# RZT2H register map
Vendor: Renesas Electronics Corporation; Series: RZT; File version: 1.00.00
CPU: other r0p0, little endian, MPU, no FPU, VTOR, 4 interrupt priority bits, 624 interrupts
Registers are 32-bit, read-write, reset 0x0 unless marked. A register's access mark holds for its fields unless they carry their own. Offsets are from the block's base; [hi:lo] are bit positions; {n}, {i} and the like mark numbered series; 'fields as' and 'values as' point back to an identical list.

## PCIE0 (part 2 of 2) — PCI Express 3.0 Interface 0
Base 0x92100000
Same registers: PCIE1 0x92110000
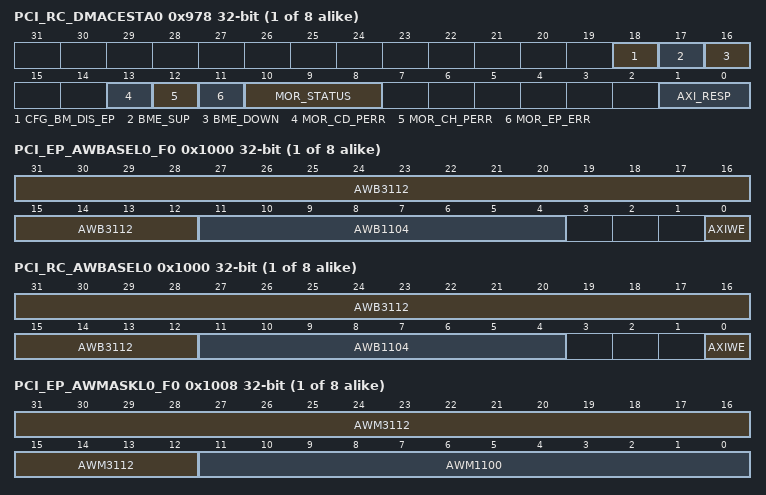
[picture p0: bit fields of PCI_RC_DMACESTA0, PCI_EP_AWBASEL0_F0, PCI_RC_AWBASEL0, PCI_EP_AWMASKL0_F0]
{0x978+0x80*i} PCI_RC_DMACESTA{i} (i=0..7) ro (alternate view of PCI_EP_DMACESTA{i}) — DMAC Error Status Register {i}
  [18] CFG_BM_DIS_EP — CHx_ERR is set when the macro operates as an End Point and detects the state of Bus Master Enable Off (Configuration Space 0x004 bit [2] = 0). Holds value until CHx_ERR is cleared.
  [17] BME_SUP — It is set when a sleep signal from the PCIe core is detected as a cause for setting CHx_ERR. Holds value until CHx_ERR is cleared.
  [16] BME_DOWN — It is set when a stop signal from the PCIe core is detected as a cause for setting CHx_ERR. Holds value until CHx_ERR is cleared.
  [13] MOR_CD_PERR — It is set when MOR_CD_PERR is detected as a set factor for CHx_ERR. Holds value until CHx_ERR is cleared.
  [12] MOR_CH_PERR — It is set when MOR_CH_PERR is detected as a set factor for CHx_ERR. Holds value until CHx_ERR is cleared.
  [11] MOR_EP_ERR — It is set when it is Poisoned Completion as a set factor of CHx_ERR. Holds value until CHx_ERR is cleared.
  [10:8] MOR_STATUS — Indicates the value when MOR_STATUS is other than 000b (Success) as a set factor of CHx_ERR. Holds value until CHx_ERR is cleared.
    0=initial value; 1=Unsupported Request; 2=CRS; 3=Completion Timeout; 4=Completer Abort; 5=Unexpected Completion; 7=Mismatched Length (Length Overrun)
  [1:0] AXI_RESP — Displays the slave response during AXI Master transactions.
    0=Initial value
{0x1000+0x20*i} PCI_EP_AWBASEL{i}_F0 (i=0..7) — AXI Window Base (Lower) Register {i} (Function #0)
  [31:12] AWB3112 — AWBase[31:12]
  [11:4] AWB1104 ro — AWBase[11:4]
  [0] AXIWE — AXI Window Enable
    0=Window disabled; 1=Window enabled
{0x1000+0x20*i} PCI_RC_AWBASEL{i} (i=0..7) (alternate view of PCI_EP_AWBASEL{i}_F0) — AXI Window Base (Lower) Register {i}
  [31:12] AWB3112 — AWBase31:12
  [11:4] AWB1104 ro — AWBase11:4
  [0] AXIWE — AXI Window Enable
    0=Window disabled; 1=Window enabled
{0x1004+0x20*i} PCI_EP_AWBASEU{i}_F0 (i=0..7) — AXI Window Base (Upper) Register {i} (Function #0)
  [31:0] AWB6332 — AWBase[63:32]
{0x1004+0x20*i} PCI_RC_AWBASEU{i} (i=0..7) (alternate view of PCI_EP_AWBASEU{i}_F0) — AXI Window Base (Upper) Register {i}
  [31:0] AWB6332 — AWBase63:32
{0x1008+0x20*i} PCI_EP_AWMASKL{i}_F0 (i=0..7) — AXI Window Mask (Lower) Register {i} (Function #0)
  [31:12] AWM3112 — AWMask[31:12]
  [11:0] AWM1100 ro — AWMask[11:0]
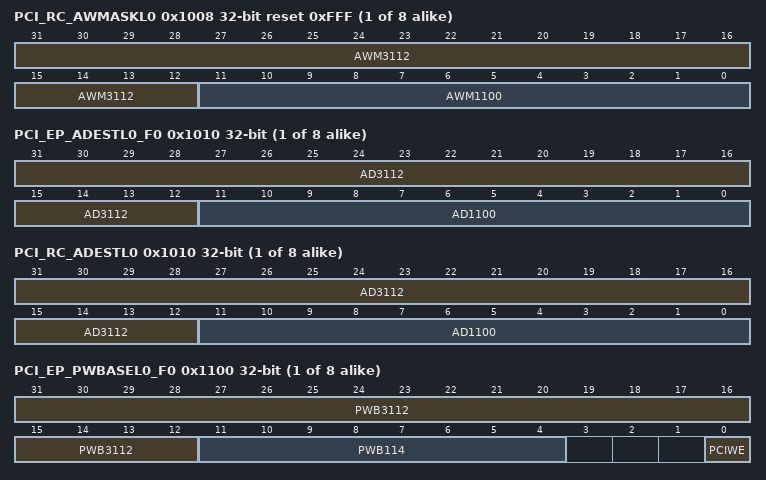
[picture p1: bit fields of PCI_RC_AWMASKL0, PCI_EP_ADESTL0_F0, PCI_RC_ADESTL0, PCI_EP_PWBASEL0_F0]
{0x1008+0x20*i} PCI_RC_AWMASKL{i} (i=0..7) reset 0xFFF (alternate view of PCI_EP_AWMASKL{i}_F0) — AXI Window Mask (Lower) Register {i}
  [31:12] AWM3112 — AWMask31:12
  [11:0] AWM1100 ro — AWMask11:0
{0x100C+0x20*i} PCI_EP_AWMASKU{i}_F0 (i=0..7) — AXI Window Mask (Upper) Register {i} (Function #0)
  [30:0] AWM6232 — AWMask[62:32]
{0x100C+0x20*i} PCI_RC_AWMASKU{i} (i=0..7) (alternate view of PCI_EP_AWMASKU{i}_F0) — AXI Window Mask Upper Register {i}
  [30:0] AWM6232 — AWMask62:32
{0x1010+0x20*i} PCI_EP_ADESTL{i}_F0 (i=0..7) — AXI Destination (Lower) Register {i} (Function #0)
  [31:12] AD3112 — ADest[31:12]
  [11:0] AD1100 ro — ADest[11:0]
{0x1010+0x20*i} PCI_RC_ADESTL{i} (i=0..7) (alternate view of PCI_EP_ADESTL{i}_F0) — AXI Destination (Lower) Register {i}
  [31:12] AD3112 — ADest31:12
  [11:0] AD1100 ro — ADest11:0
{0x1014+0x20*i} PCI_EP_ADESTU{i}_F0 (i=0..7) — AXI Destination (Upper) Register {i} (Function #0)
  [31:0] AD6332 — ADest[63:32]
{0x1014+0x20*i} PCI_RC_ADESTU{i} (i=0..7) (alternate view of PCI_EP_ADESTU{i}_F0) — AXI Destination (Upper) Register {i}
  [31:0] AD6332 — ADest63:32
{0x1100+0x20*i} PCI_EP_PWBASEL{i}_F0 (i=0..7) — PCIe Window Base (Lower) Register {i} (Function #0)
  [31:12] PWB3112 — PWBase[31:12]
  [11:4] PWB114 ro — PWBase[11:4]
  [0] PCIWE — PCIe Window Enable
    0=Window disabled; 1=Window enabled
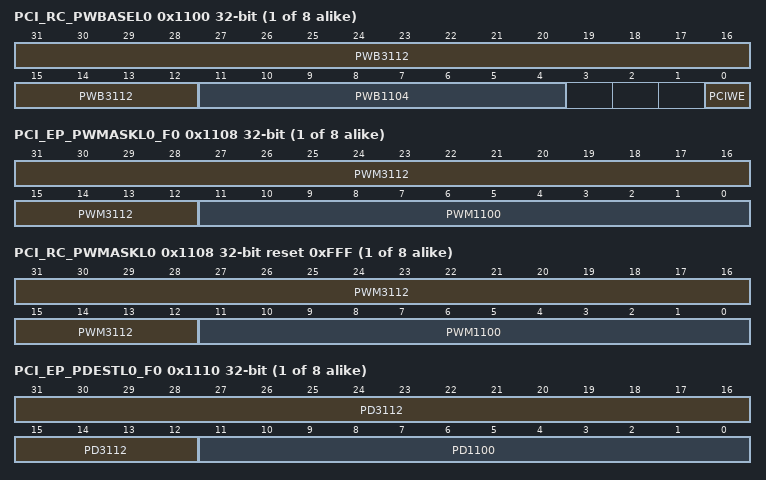
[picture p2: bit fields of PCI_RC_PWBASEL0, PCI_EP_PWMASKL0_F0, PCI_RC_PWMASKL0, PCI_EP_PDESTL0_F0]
{0x1100+0x20*i} PCI_RC_PWBASEL{i} (i=0..7) (alternate view of PCI_EP_PWBASEL{i}_F0) — PCIe Window Base (Lower) Register {i}
  [31:12] PWB3112 — PWBase31:12
  [11:4] PWB1104 ro — PWBase11:4
  [0] PCIWE — PCIe Window Enable
    0=Window disabled; 1=Window enabled
{0x1104+0x20*i} PCI_EP_PWBASEU{i}_F0 (i=0..7) — PCIe Window Base (Upper) Register {i} (Function #0)
  [31:0] PWB6332 — PWBase[63:32]
{0x1104+0x20*i} PCI_RC_PWBASEU{i} (i=0..7) (alternate view of PCI_EP_PWBASEU{i}_F0) — PCIe Window Base (Upper) Register {i}
  [31:0] PWB6332 — PWBase63:32
{0x1108+0x20*i} PCI_EP_PWMASKL{i}_F0 (i=0..7) — PCIe Window Mask (Lower) Register {i} (Function #0)
  [31:12] PWM3112 — PWMask[31:12]
  [11:0] PWM1100 ro — PWMask[11:0]
{0x1108+0x20*i} PCI_RC_PWMASKL{i} (i=0..7) reset 0xFFF (alternate view of PCI_EP_PWMASKL{i}_F0) — PCIe Window Mask (Lower) Register {i}
  [31:12] PWM3112 — PWMask31:12
  [11:0] PWM1100 ro — PWMask
{0x110C+0x20*i} PCI_EP_PWMASKU{i}_F0 (i=0..7) — PCIe Window Mask (Upper) Register {i} (Function #0)
  [30:0] PWM6232 — PWMask[62:32]
{0x110C+0x20*i} PCI_RC_PWMASKU{i} (i=0..7) (alternate view of PCI_EP_PWMASKU{i}_F0) — PCIe Window Mask (Upper) Register {i}
  [30:0] PWM6232 — PWMask62:32
{0x1110+0x20*i} PCI_EP_PDESTL{i}_F0 (i=0..7) — PCIe Destination (Lower) Register {i} (Function #0)
  [31:12] PD3112 — PDest[31:12]
  [11:0] PD1100 ro — PDest[11:0]
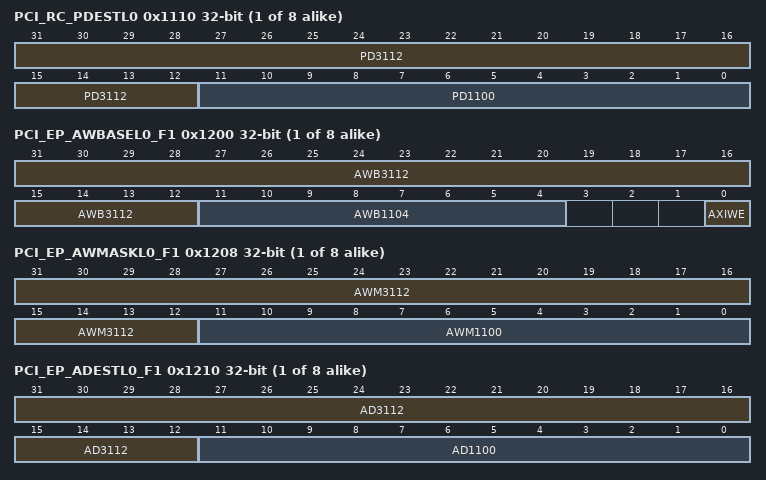
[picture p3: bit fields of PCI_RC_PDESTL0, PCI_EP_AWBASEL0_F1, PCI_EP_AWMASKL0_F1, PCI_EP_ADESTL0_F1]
{0x1110+0x20*i} PCI_RC_PDESTL{i} (i=0..7) (alternate view of PCI_EP_PDESTL{i}_F0) — PCIe Destination (Lower) Register {i}
  [31:12] PD3112 — PDest31:12
  [11:0] PD1100 ro — PDest11:0
{0x1114+0x20*i} PCI_EP_PDESTU{i}_F0 (i=0..7) — PCIe Destination (Upper) Register {i} (Function #0)
  [31:0] PD6332 — PDest[63:32]
{0x1114+0x20*i} PCI_RC_PDESTU{i} (i=0..7) (alternate view of PCI_EP_PDESTU{i}_F0) — PCIe Destination (Upper) Register {i}
  [31:0] PD6332 — PDest63:32
{0x1200+0x20*i} PCI_EP_AWBASEL{i}_F1 (i=0..7) — AXI Window Base (Lower) Register {i} (Function #1)
  fields as PCI_EP_AWBASEL0_F0
{0x1204+0x20*i} PCI_EP_AWBASEU{i}_F1 (i=0..7) — AXI Window Base (Upper) Register {i} (Function #1)
  [31:0] AWB6332 — AWBase[63:32]
{0x1208+0x20*i} PCI_EP_AWMASKL{i}_F1 (i=0..7) — AXI Window Mask (Lower) Register {i} (Function #1)
  [31:12] AWM3112 — AWMask[31:12]
  [11:0] AWM1100 ro — AWMask[11:0]
{0x120C+0x20*i} PCI_EP_AWMASKU{i}_F1 (i=0..7) — AXI Window Mask (Upper) Register {i} (Function #1)
  [30:0] AWM6232 — AWMask[62:32]
{0x1210+0x20*i} PCI_EP_ADESTL{i}_F1 (i=0..7) — AXI Destination (Lower) Register {i} (Function #1)
  [31:12] AD3112 — ADest[31:12]
  [11:0] AD1100 ro — ADest[11:0]
{0x1214+0x20*i} PCI_EP_ADESTU{i}_F1 (i=0..7) — AXI Destination (Upper) Register {i} (Function #1)
  [31:0] AD6332 — ADest[63:32]
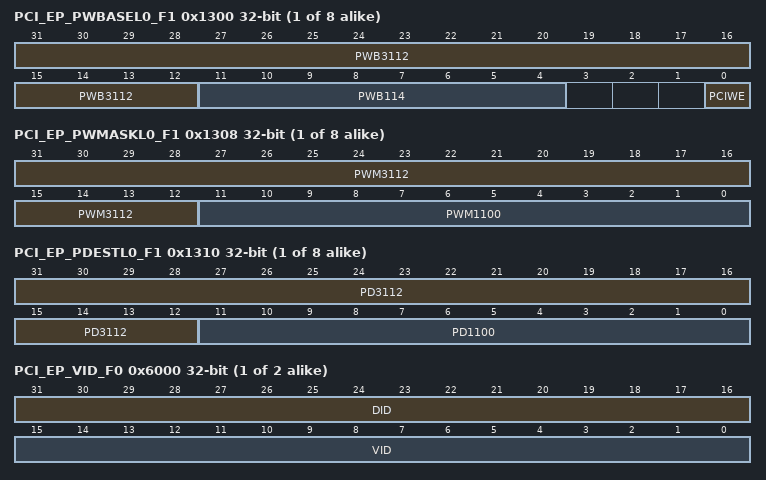
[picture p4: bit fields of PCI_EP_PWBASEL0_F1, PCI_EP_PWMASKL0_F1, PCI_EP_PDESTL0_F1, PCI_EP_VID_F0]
{0x1300+0x20*i} PCI_EP_PWBASEL{i}_F1 (i=0..7) — PCIe Window Base (Lower) Register {i} (Function #1)
  fields as PCI_EP_PWBASEL0_F0
{0x1304+0x20*i} PCI_EP_PWBASEU{i}_F1 (i=0..7) — PCIe Window Base (Upper) Register {i} (Function #1)
  [31:0] PWB6332 — PWBase[63:32]
{0x1308+0x20*i} PCI_EP_PWMASKL{i}_F1 (i=0..7) — PCIe Window Mask (Lower) Register {i} (Function #1)
  [31:12] PWM3112 — PWMask[31:12]
  [11:0] PWM1100 ro — PWMask[11:0]
{0x130C+0x20*i} PCI_EP_PWMASKU{i}_F1 (i=0..7) — PCIe Window Mask (Upper) Register {i} (Function #1)
  [30:0] PWM6232 — PWMask[62:32]
{0x1310+0x20*i} PCI_EP_PDESTL{i}_F1 (i=0..7) — PCIe Destination (Lower) Register {i} (Function #1)
  [31:12] PD3112 — PDest[31:12]
  [11:0] PD1100 ro — PDest[11:0]
{0x1314+0x20*i} PCI_EP_PDESTU{i}_F1 (i=0..7) — PCIe Destination (Upper) Register {i} (Function #1)
  [31:0] PD6332 — PDest[63:32]
{0x6000+0x1000*i} PCI_EP_VID_F{i} (i=0..1) — Vendor and Device ID (Function #i)
  [31:16] DID — Device ID
  [15:0] VID — Vendor ID
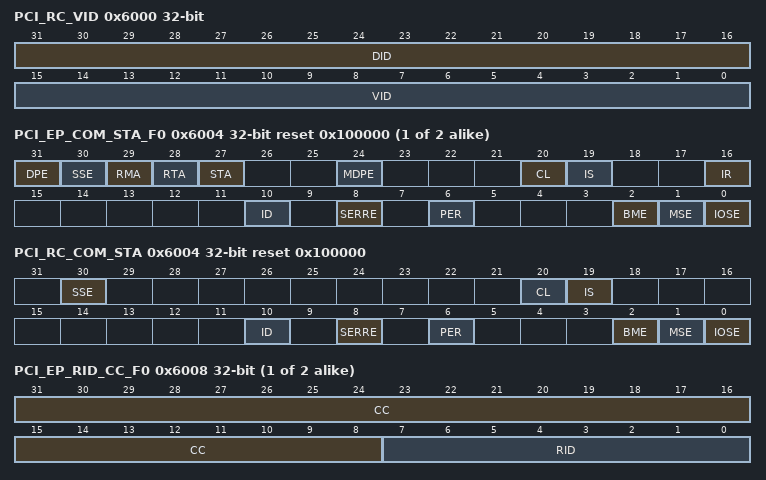
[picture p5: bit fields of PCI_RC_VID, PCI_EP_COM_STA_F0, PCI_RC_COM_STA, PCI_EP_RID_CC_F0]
0x6000 PCI_RC_VID — Vendor and Device ID Register
  [31:16] DID — Device ID
  [15:0] VID — Vendor ID
{0x6004+0x1000*i} PCI_EP_COM_STA_F{i} (i=0..1) reset 0x100000 — Command and Status (Function #i)
  [31] DPE — Detected Parity Error
  [30] SSE — Signaled System Error
  [29] RMA — Received Master Abort
  [28] RTA — Received Target Abort
  [27] STA — Signaled Target Abort
  [24] MDPE — Master Data Parity Error
  [20] CL ro — Capabilities List
  [19] IS ro — Interrupt Status
  [16] IR ro — Fixed 0
  [10] ID — Interrupt Disable
  [8] SERRE — SERR# Enable
  [6] PER — Parity Error Response
  [2] BME — Bus Master Enable
  [1] MSE — Memory Space Enable
  [0] IOSE ro — IO Space Enable
0x6004 PCI_RC_COM_STA reset 0x100000 — Command and Status Register
  [30] SSE — Signaled System Error
  [20] CL ro — Capabilities List
  [19] IS ro — Interrupt Status
  [10] ID — Interrupt Disable
  [8] SERRE — SERR# Enable
  [6] PER — Parity Error Response
  [2] BME — Bus Master Enable
  [1] MSE — Memory Space Enable
  [0] IOSE ro — IO Space Enable
{0x6008+0x1000*i} PCI_EP_RID_CC_F{i} (i=0..1) — Revision ID and Class Code (Function #i)
  [31:8] CC — Class Code
  [7:0] RID — Revision ID
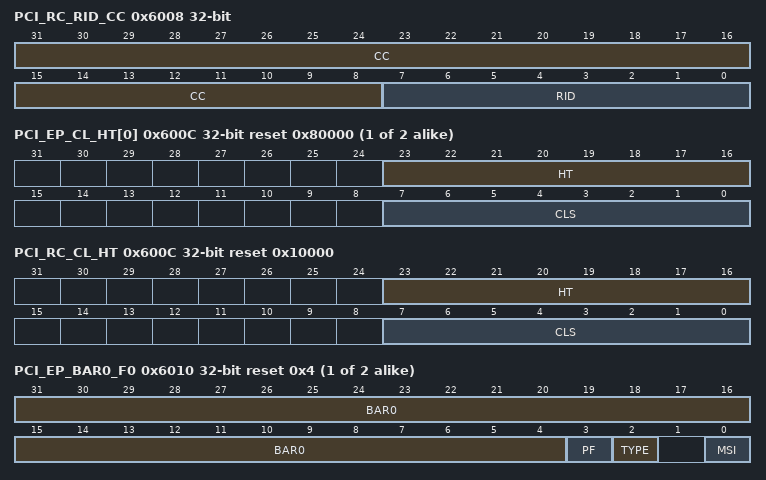
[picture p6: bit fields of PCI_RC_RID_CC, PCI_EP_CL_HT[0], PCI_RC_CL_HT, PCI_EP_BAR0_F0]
0x6008 PCI_RC_RID_CC — Revision ID and Class Code Register
  [31:8] CC — Class Code
  [7:0] RID — Revision ID
{0x600C+0x1000*i} PCI_EP_CL_HT[{i}] (i=0..1) ro reset 0x80000 — Cache Line and Header Type (Function #i)
  [23:16] HT — Header Type
  [7:0] CLS — Cache Line Size
0x600C PCI_RC_CL_HT ro reset 0x10000 — Cache Line and Header Type Register
  [23:16] HT — Header Type
  [7:0] CLS — Cache Line Size
{0x6010+0x1000*i} PCI_EP_BAR0_F{i} (i=0..1) reset 0x4 — Base Address Register 0 (Function #i)
  [31:4] BAR0 — Base Address Register 0
  [3] PF — Prefetch
    0=Disable; 1=Enable
  [2] TYPE
    0=32-bit address; 1=64-bit address
  [0] MSI — Memory Space Indicator
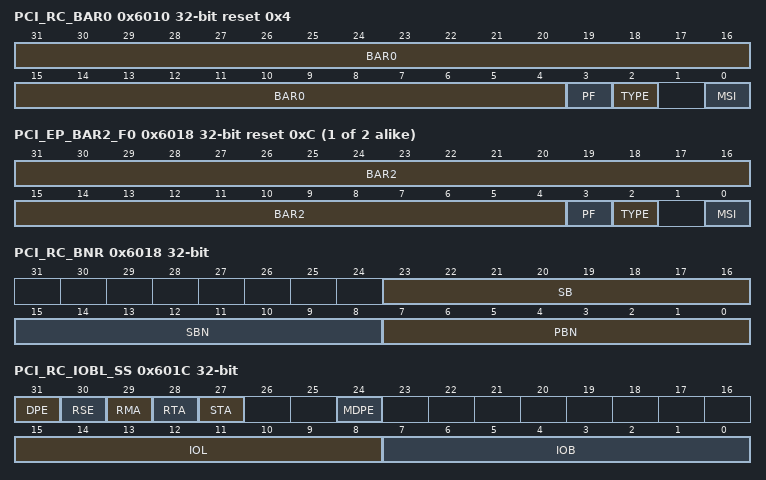
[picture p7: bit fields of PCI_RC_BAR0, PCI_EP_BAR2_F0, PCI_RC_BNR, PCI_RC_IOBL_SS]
0x6010 PCI_RC_BAR0 reset 0x4 — Base Address Register 0
  [31:4] BAR0 — Base Address Register 0
  [3] PF — Prefetch
    0=Disable; 1=Enable
  [2] TYPE ro
    0=32-bit address; 1=64-bit address
  [0] MSI ro — Memory Space Indicator
{0x6014+0x1000*i} PCI_EP_BAR1_F{i} (i=0..1) — Base Address Register 1 (Function #i)
  [31:0] BAR1 — Base Address Register 1 (64-bit Upper Address)
0x6014 PCI_RC_BAR1 — Base Address Register 1
  [31:0] BAR1 — Base Address Register 1 (64-bit Upper Address)
{0x6018+0x1000*i} PCI_EP_BAR2_F{i} (i=0..1) reset 0xC — Base Address Register 2 (Function #i)
  [31:4] BAR2 — Base Address Register 2
  [3] PF — Prefetch
    0=Disable; 1=Enable
  [2] TYPE
    0=32-bit address; 1=64-bit address
  [0] MSI ro — Memory Space Indicator
0x6018 PCI_RC_BNR — Bus Number Register
  [23:16] SB — Subordinate Bus
  [15:8] SBN — Secondary Bus Number
  [7:0] PBN — Primary Bus Number
{0x601C+0x1000*i} PCI_EP_BAR3_F{i} (i=0..1) — Base Address Register 3 (Function #i)
  [31:0] BAR3 — Base Address Register 3 (64-bit Upper Address)
0x601C PCI_RC_IOBL_SS — I/O Base/ Limit and Secondary Status
  [31] DPE — Detected Parity Error
  [30] RSE — Received System Error
  [29] RMA — Received Master Abort
  [28] RTA — Received Target Abort
  [27] STA — Signaled Target Abort
  [24] MDPE — Master Data Parity Error
  [15:8] IOL — IO Limit
  [7:0] IOB — IO Base
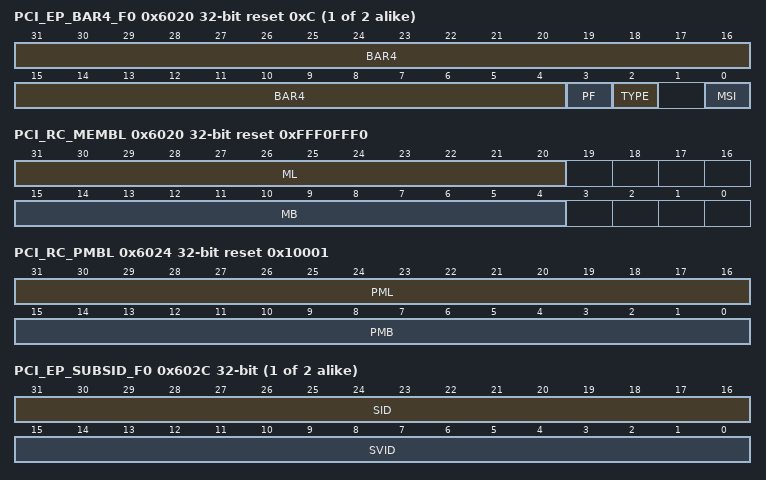
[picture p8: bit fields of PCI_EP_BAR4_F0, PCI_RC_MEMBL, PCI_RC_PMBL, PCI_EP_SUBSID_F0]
{0x6020+0x1000*i} PCI_EP_BAR4_F{i} (i=0..1) reset 0xC — Base Address Register 4 (Function #i)
  [31:4] BAR4 — Base Address Register 4
  [3] PF — Prefetch
    0=Disable; 1=Enable
  [2] TYPE
    0=32-bit address; 1=64-bit address
  [0] MSI ro — Memory Space Indicator
0x6020 PCI_RC_MEMBL reset 0xFFF0FFF0 — Memory Base/ Limit Register
  [31:20] ML — Memory Limit
  [15:4] MB — Memory Base
{0x6024+0x1000*i} PCI_EP_BAR5_F{i} (i=0..1) — Base Address Register 5 (Function #i)
  [31:0] BAR5 — Base Address Register 5 (64-bit Upper Address)
0x6024 PCI_RC_PMBL reset 0x10001 — Prefetchable Memory Base/ Limit Register
  [31:16] PML — Prefetchable Memory Limit
  [15:0] PMB — Prefetchable Memory Base
0x6028 PCI_RC_PBUP32 — Prefetchable Base Upper 32 Bits Register
{0x602C+0x1000*i} PCI_EP_SUBSID_F{i} (i=0..1) — Subsystem ID (Function #i)
  [31:16] SID — Subsystem ID
  [15:0] SVID — Subsystem Vendor ID
0x602C PCI_RC_PLUP32 — Prefetchable Limit Upper 32 Bits Register
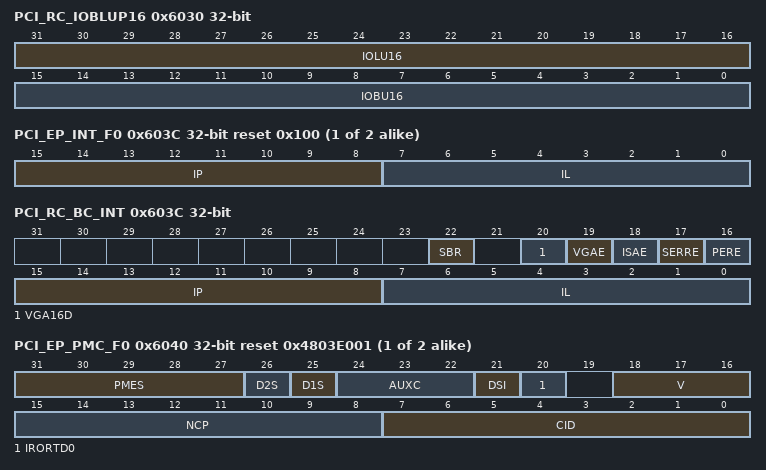
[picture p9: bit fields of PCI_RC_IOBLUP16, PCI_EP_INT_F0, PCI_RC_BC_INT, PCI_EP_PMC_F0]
0x6030 PCI_RC_IOBLUP16 — I/O Base/Limit Upper 16 bits Register
  [31:16] IOLU16 — IO Limit Upper 16 bits
  [15:0] IOBU16 — IO Base Upper 16 bits
{0x6034+0x1000*i} PCI_EP_CP_F{i} (i=0..1) ro reset 0x40 — Capabilities Pointer (Function #i)
  [7:0] CP — Capabilities Pointer
0x6034 PCI_RC_CP reset 0x40 — Capabilities Pointer Register
  [7:0] CP — Capability Pointer
{0x603C+0x1000*i} PCI_EP_INT_F{i} (i=0..1) reset 0x100 — Interrupt Register (Function #i)
  [15:8] IP — Interrupt Pin
    1=Assert_INTA# (default); 2=Assert_INTB#; 3=Assert_INTC#; 4=Assert_INTD#; other=Others (Reserved)
  [7:0] IL — Interrupt Line
0x603C PCI_RC_BC_INT — Bridge Control and Interrupt
  [22] SBR — Secondary Bus Reset
  [20] VGA16D — VGA 16-bit Decode
  [19] VGAE — VGA Enable
  [18] ISAE — ISA Enable
  [17] SERRE — SERR# Enable
  [16] PERE — Parity Error Response Enable
  [15:8] IP — Interrupt Pin
  [7:0] IL — Interrupt Line
{0x6040+0x1000*i} PCI_EP_PMC_F{i} (i=0..1) reset 0x4803E001 — PM Capabilities (Function #i)
  [31:27] PMES — PME Support
    0bxxxx1=Supports D0; 0bxxx1x=Supports D1; 0bxx1xx=Supports D2; 0bx1xxx=Support D3hot; 0b1xxxx=D3cold supported (not supported)
  [26] D2S — D2 Support
    0=Not supported; 1=Support
  [25] D1S — D1 Support
    0=Not supported; 1=Support
  [24:22] AUXC — AUX_Current
    0=0 (self powered); 1=55 mA; 2=100 mA; 3=160 mA; 4=220 mA; 5=250 mA; 6=320 mA; 7=375 mA
  [21] DSI — Device Specific Initialization
    0=Not supported; 1=Support
  [20] IRORTD0 ro — Immediate_Readiness_on_Return_to_D0
  [18:16] V — Version
  [15:8] NCP ro — Next Capability Pointer
  [7:0] CID ro — Capability ID
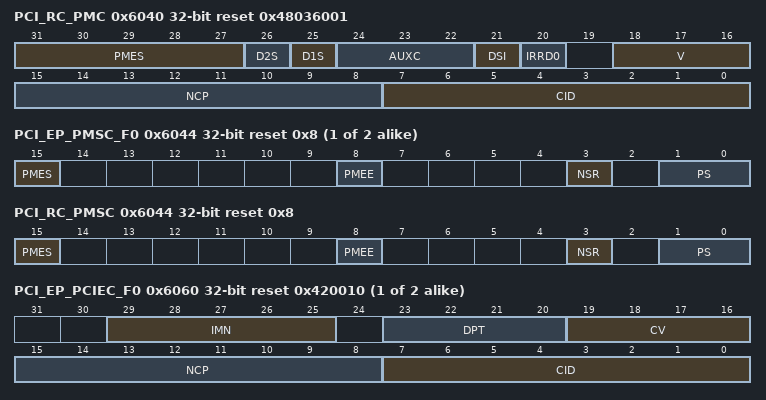
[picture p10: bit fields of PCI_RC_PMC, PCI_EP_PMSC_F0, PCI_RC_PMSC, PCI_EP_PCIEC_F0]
0x6040 PCI_RC_PMC reset 0x48036001 — PM Capabilities
  [31:27] PMES — PME Support
  [26] D2S — D2 Support
    0=not supported; 1=Support
  [25] D1S — D1 Support
    0=not supported; 1=Support
  [24:22] AUXC — AUX_Current
    values as PCI_EP_PMC_F0.AUXC
  [21] DSI — Device Specific Initialization (DSI)
    0=not supported; 1=Support
  [20] IRRD0 ro — Immediate_Readiness_on_Return_to_D0
  [18:16] V — Version
  [15:8] NCP ro — Next Capability Pointer
  [7:0] CID ro — Capability ID
{0x6044+0x1000*i} PCI_EP_PMSC_F{i} (i=0..1) reset 0x8 — PM Status/Control (Function #i)
  [15] PMES — PME Status
  [8] PMEE — PME Enable
  [3] NSR ro — No_Soft_Reset
  [1:0] PS — PowerState
    0=D0 (Default); 1=D1 (Do not set); 2=D2 (Do not set); 3=D3hot
0x6044 PCI_RC_PMSC reset 0x8 — PM Status/Control Register
  fields as PCI_EP_PMSC_F0
{0x6060+0x1000*i} PCI_EP_PCIEC_F{i} (i=0..1) reset 0x420010 — PCI Express Capability (Function #i)
  [29:25] IMN — Interrupt Message Number
  [23:20] DPT — DevicePort Type
    0=PCI Express Endpoint device; 1=Legacy PCI Express Endpoint device; 4=Root Port of PCI Express Root Complex (Default); 5=Upstream Port of PCI Express Switch; 6=Downstream Port of PCI Express Switch; 7=PCI Express-to-PCI/PCI-X Bridge; 8=PCI/PCI-X-to-PCI Express Bridge; 9=Root Complex Integrated Endpoint Device; 10=Root Complex Event Collector; other=Others (Reserved)
  [19:16] CV — Capability Version
  [15:8] NCP ro — Next Capability Pointer
  [7:0] CID ro — Capability ID
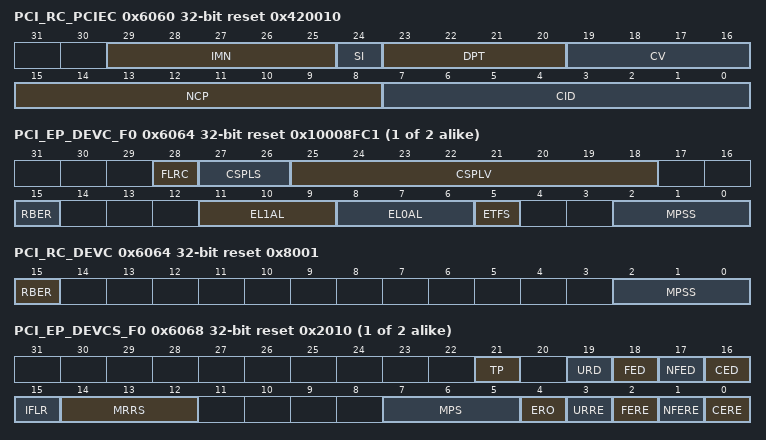
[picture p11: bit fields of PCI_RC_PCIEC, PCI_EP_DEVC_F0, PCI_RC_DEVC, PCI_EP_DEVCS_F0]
0x6060 PCI_RC_PCIEC reset 0x420010 — PCI Express Capability Register
  [29:25] IMN ro — Interrupt Message Number
  [24] SI — Slot Implemented
  [23:20] DPT ro — DevicePort Type
    values as PCI_EP_PCIEC_F0.DPT
  [19:16] CV — Capability Version
  [15:8] NCP — Next Capability Pointer
  [7:0] CID ro — Capability ID
{0x6064+0x1000*i} PCI_EP_DEVC_F{i} (i=0..1) reset 0x10008FC1 — Device Capabilities (Function #i)
  [28] FLRC — Function Level Reset Capability
  [27:26] CSPLS — Captured Slot Power Limit Scale
  [25:18] CSPLV — Captured Slot Power Limit Value
  [15] RBER ro — Role-Based Error Reporting
  [11:9] EL1AL — Endpoint L1 Acceptable Latency
    0=max 1 us; 1=max 2 us; 2=max 4 us; 3=max 8 us; 4=max 16 us; 5=max 32 us; 6=max 64 us; 7=No limit (Default)
  [8:6] EL0AL — Endpoint L0 Acceptable Latency
    0=max 64 ns; 1=max 128 ns; 2=max 256 ns; 3=max 512 ns; 4=max 1 us; 5=max 2 us; 6=max 4 us; 7=No limit (Default)
  [5] ETFS — Extended Tag Field Supported
    0=5-bit Tag field supported (Default); 1=8-bit Tag field supported
  [2:0] MPSS — Max_Payload_Size Supported
    0=128 B max payload size; 1=256 B max payload size (Default); 2=512 B max payload size; 3=1024 B max payload size; 4=2048 B max payload size; 5=4096 B max payload size
0x6064 PCI_RC_DEVC reset 0x8001 — Device Capabilities Register
  [15] RBER ro — Role-Based Error Reporting
  [2:0] MPSS — Max_Payload_Size Supported
    values as PCI_EP_DEVC_F0.MPSS
{0x6068+0x1000*i} PCI_EP_DEVCS_F{i} (i=0..1) reset 0x2010 — Device Control/Status (Function #i)
  [21] TP ro — Transaction Pending
  [19] URD — Unsupported Request Detected
  [18] FED — Fatal Error Detected
  [17] NFED — Non-Fatal Error Detected
  [16] CED — Correctable Error Detected
  [15] IFLR — Initiate Function Level Reset
  [14:12] MRRS — Max_Read_Request_Size
    0=128 B max read request size; 1=256 B max read request size; 2=512 B max read request size (Default); 3=1024 B max read request size; 4=2048 B max read request size; 5=4096 B max read request size
  [7:5] MPS — Max_Payload_Size
    0=128 B max payload size (Default); 1=256 B max payload size; 2=512 B max payload size; 3=1024 B max payload size; 4=2048 B max payload size; 5=4096 B max payload size
  [4] ERO — Enable Relaxed Ordering
    0=Not supported; 1=Support (Default)
  [3] URRE — Unsupported Request Reporting Enable
  [2] FERE — Fatal Error Reporting Enable
  [1] NFERE — Non-Fatal Error Reporting Enable
  [0] CERE — Correctable Error Reporting Enable
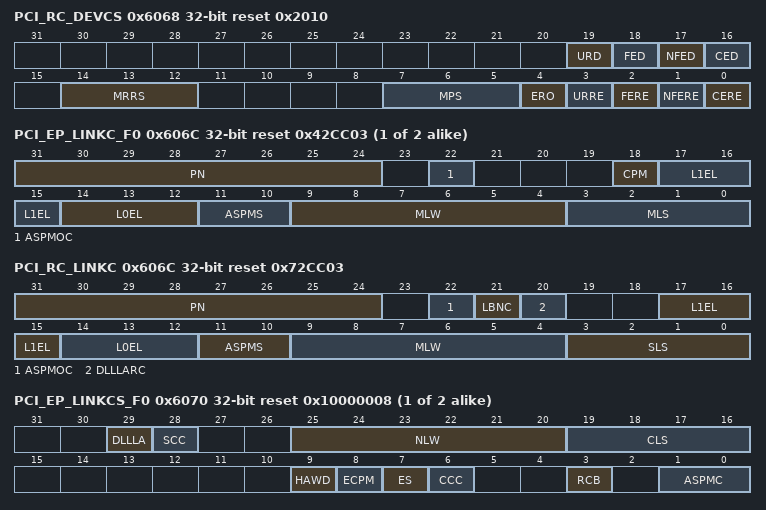
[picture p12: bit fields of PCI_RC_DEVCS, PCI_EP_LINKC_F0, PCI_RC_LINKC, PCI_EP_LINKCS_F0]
0x6068 PCI_RC_DEVCS reset 0x2010 — Device Control/Status Register
  [19] URD — Unsupported Request Detected
  [18] FED — Fatal Error Detected
  [17] NFED — Non-Fatal Error Detected
  [16] CED — Correctable Error Detected
  [14:12] MRRS — Max_Read_Request_Size
    values as PCI_EP_DEVCS_F0.MRRS
  [7:5] MPS — Max_Payload_Size
    values as PCI_EP_DEVCS_F0.MPS
  [4] ERO — Enable Relaxed Ordering
    0=Not supported; 1=Support
  [3] URRE — Unsupported Request Reporting Enable
  [2] FERE — Fatal Error Reporting Enable
  [1] NFERE — Non-Fatal Error Reporting Enable
  [0] CERE — Correctable Error Reporting Enable
{0x606C+0x1000*i} PCI_EP_LINKC_F{i} (i=0..1) reset 0x42CC03 (reset mask 0xFFFFFFCF) — Link Capabilities (Function #i)
  [31:24] PN — Port Number
  [22] ASPMOC — ASPM Optionality Compliance
  [18] CPM — Clock Power Management
    0=CLKREQ# mechanism not supported; 1=Supports CLKREQ# mechanism. (Setting prohibited)
  [17:15] L1EL — L1 Exit Latency
    0=Less than 1 us; 1=1 us to less than 2 us; 2=2 us to less than 4 us; 3=4 us to less than 8 us; 4=8 us to less than 16 us; 5=16 us to less than 32 us (Default); 6=32 us to 64 us; 7=More than 64 us
  [14:12] L0EL — L0s Exit Latency
    0=Less than 64 ns; 1=64 ns to less than 128 ns; 2=128 ns to less than 256 ns; 3=256 ns to less than 512 ns; 4=512 ns to less than 1 us (Default); 5=1 us to less than 2 us; 6=2 us to 4 us; 7=More than 4 us
  [11:10] ASPMS — Active State Power Management (ASPM) Support
    1=L0s Entry Supported; 2=L1 Entry Supported; 3=L0s and L1 Entry Supported (Default)
  [9:4] MLW — Maximum Link Width
    1=x1 (Default when using ch1.); 2=x2 (Default when using ch0. Don't set for ch1.); 4=x4 (prohibited); 8=x8 (prohibited); 12=x12 (prohibited); 16=x16 (prohibited); 32=x32 (prohibited)
  [3:0] MLS — Max Link Speed
    1=2.5 GT/s Link speed supported; 2=5.0 GT/s and 2.5 GT/s Link speeds supported; 3=8.0 GT/s Link speed supported (Default); 4=16.0 GT/s Link speed supported (prohibited); other=Others (Reserved)
0x606C PCI_RC_LINKC reset 0x72CC03 (reset mask 0xFFFFFFCF) — Link Capabilities Register
  [31:24] PN — Port Number
  [22] ASPMOC — ASPM Optionality Compliance
  [21] LBNC — Link Bandwidth Notification Capability
  [20] DLLLARC — Data Link Layer Link Active Reporting Capable
  [17:15] L1EL — L1 Exit Latency
    0=Less than 1 us; 1=1 us to less than 2 us; 2=2 us to less than 4 us; 3=4 us to less than 8 us; 4=8 us to less than 16 us; 5=16 us to less than 32 us (default); 6=32 us to 64 us; 7=More than 64 us
  [14:12] L0EL — L0s Exit Latency
    0=Less than 64 ns; 1=64 ns to less than 128 ns; 2=128 ns to less than 256 ns; 3=256 ns to less than 512 ns; 4=512 ns to less than 1 us (default); 5=1 us to less than 2 us; 6=2 us to 4 us; 7=More than 4 us
  [11:10] ASPMS — Active State Power Management (ASPM) Support
    1=L0s entry supported; 2=L1 entry supported; 3=L0s and L1 entry supported (default)
  [9:4] MLW — Maximum Link Width
    1=x1 (Default when using ch1.); 2=x2 (Default when using ch0. Do not set for ch1.); 4=x4 (prohibited); 8=x8 (prohibited); 12=x12 (prohibited); 16=x16 (prohibited); 32=x32 (prohibited)
  [3:0] SLS — Supported Link Speed
    1=2.5 GT/s link speed supported; 2=5.0 GT/s and 2.5 GT/s Link speeds supported; 3=8.0 GT/s link speed supported (default); 4=16.0 GT/s link speed supported (prohibited); other=Others (Reserved)
{0x6070+0x1000*i} PCI_EP_LINKCS_F{i} (i=0..1) reset 0x10000008 — Link Control/Status (Function #i)
  [29] DLLLA ro — Data Link Layer Link Active
  [28] SCC — Slot Clock Configuration
    0=Not using Connector Reference Clock; 1=Use Connector Reference Clock (Default)
  [25:20] NLW ro — Negotiated Link Width
    1=x1; 2=x2; 4=x4; 8=x8; 12=x12; 16=x16; 32=x32; other=Others (Reserved)
  [19:16] CLS ro — Current Link Speed
    0=During reset period; 1=2.5 GT/s PCI Express Link; 2=5.0 GT/s PCI Express Link; 3=8.0 GT/s PCI Express Link; 4=16.0 GT/s PCI Express Link
  [9] HAWD — Hardware Autonomous Width Disable
    0=Enable of Link Width Change; 1=Disable
  [8] ECPM — Enable Clock Power Management
  [7] ES — Extended Synch
  [6] CCC — Common Clock Configuration
    0=Provided by non-Common Reference Clock (Default); 1=Supplied by Common Reference Clock
  [3] RCB — Read Completion Boundary (RCB)
    0=64 bytes; 1=128 bytes (Default)
  [1:0] ASPMC — Active State Power Management (ASPM) Control
    0=Disabled (Default); 1=L0s Entry Supported; 2=L1 Entry Supported; 3=L0s and L1 Entry Supported
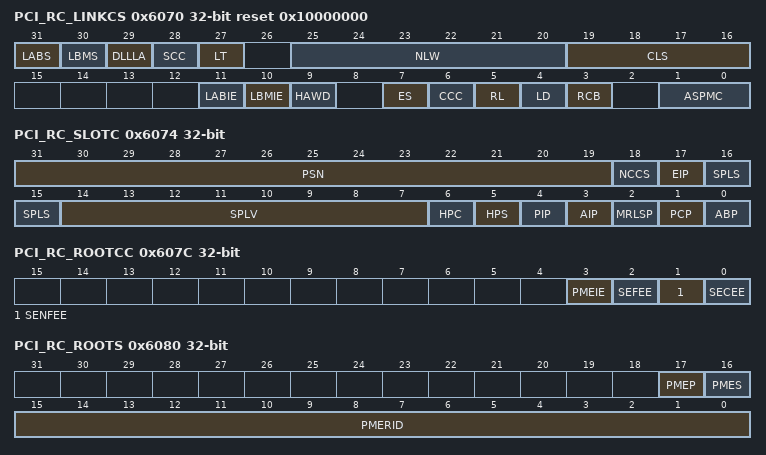
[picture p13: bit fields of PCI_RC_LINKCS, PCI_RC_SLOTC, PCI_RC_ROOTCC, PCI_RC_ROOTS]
0x6070 PCI_RC_LINKCS reset 0x10000000 — Link Control/Status Register
  [31] LABS — Link Autonomous Bandwidth Status
  [30] LBMS — Link Bandwidth Management Status
  [29] DLLLA ro — Data Link Layer Link Active
  [28] SCC — Slot Clock Configuration
    0=Do not use Connector Reference Clock; 1=Use Connector Reference Clock (Default)
  [27] LT ro — Link Training
  [25:20] NLW ro — Negotiated Link Width
    values as PCI_EP_LINKCS_F0.NLW
  [19:16] CLS ro — Current Link Speed
    values as PCI_EP_LINKCS_F0.CLS
  [11] LABIE — Link Autonomous Bandwidth Interrupt Enable
    0=Interrupt Disable (Default); 1=Interrupt Enable
  [10] LBMIE — Link Bandwidth Management Interrupt Enable
    0=Interrupt Disable (Default); 1=Interrupt Enable
  [9] HAWD — Hardware Autonomous Width Disable
    0=Link Width Change Enable (Default); 1=Link Width Change Disable
  [7] ES — Extended Synch
  [6] CCC — Common Clock Configuration
    values as PCI_EP_LINKCS_F0.CCC
  [5] RL — Retrain Link
  [4] LD — Link Disable
  [3] RCB ro — Read Completion Boundary (RCB)
    0=64 bytes; 1=128 bytes (Default)
  [1:0] ASPMC — Active State Power Management (ASPM) Control
    values as PCI_EP_LINKCS_F0.ASPMC
0x6074 PCI_RC_SLOTC — Slot Capabilities
  [31:19] PSN — Physical Slot Number
  [18] NCCS — No Command Completed Support
  [17] EIP — Electromechanical Interlock Present
  [16:15] SPLS — Slot Power Limit Scale
    0=1.0x; 1=0.1x; 2=0.01x; 3=0.001x
  [14:7] SPLV — Slot Power Limit Value
    240=250 W Slot Power Limit; 241=275 W Slot Power Limit; 242=300 W Slot Power Limit; other=Others (reserved)
  [6] HPC — Hot-Plug Capable
  [5] HPS — Hot-Plug Surprise
  [4] PIP — Power Indicator Present
  [3] AIP — Attention Indicator Present
  [2] MRLSP — MRL Sensor Present
  [1] PCP — Power Control Present
  [0] ABP — Attention Button Present
0x6078 PCI_RC_SLOTCS ro reset 0x400000 — Slot Control/Status
0x607C PCI_RC_ROOTCC — Root Control/Capabilities
  [3] PMEIE — PME Interrupt Enable
  [2] SEFEE — System Error on Fatal Error Enable
  [1] SENFEE — System Error on Non-Fatal Error Enable
  [0] SECEE — System Error on Correctable Error Enable
0x6080 PCI_RC_ROOTS — Root Status
  [17] PMEP ro — PME Pending
  [16] PMES — PME Status
  [15:0] PMERID ro — PME Requester ID
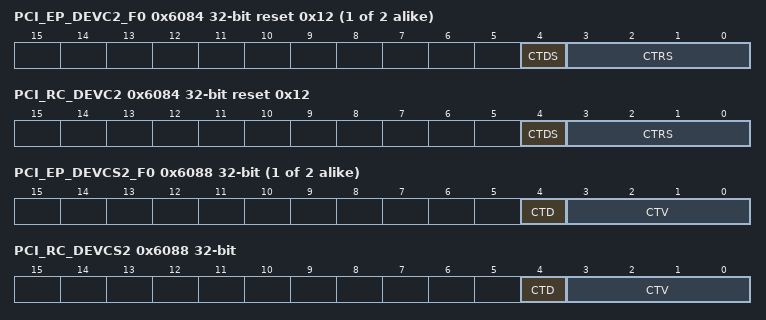
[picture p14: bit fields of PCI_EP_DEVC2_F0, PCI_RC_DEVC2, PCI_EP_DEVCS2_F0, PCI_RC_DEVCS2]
{0x6084+0x1000*i} PCI_EP_DEVC2_F{i} (i=0..1) reset 0x12 — Device Capabilities 2 (Function #i)
  [4] CTDS — Completion Timeout Disable Supported
    0=Not supported; 1=Supported (default)
  [3:0] CTRS — Completion Timeout Ranges Supported
    0=Program setting Not supported; 1=Range A; 2=Range B; 3=Ranges A and B; 6=Ranges B and C; 7=Ranges A, B, and C; 14=Ranges B, C and D; 15=Ranges A, B, C, and D; other=Others (Reserved)
0x6084 PCI_RC_DEVC2 reset 0x12 — Device Capabilities 2 Register
  fields as PCI_EP_DEVC2_F0
{0x6088+0x1000*i} PCI_EP_DEVCS2_F{i} (i=0..1) — Device Control 2/Status 2 (Function #i)
  [4] CTD — Completion Timeout Disable
  [3:0] CTV — Completion Timeout Value
    0=10 ms to 50 ms (default); 1=50 us to 100 us; 2=1 ms to 10 ms; 5=16 ms to 55 ms; 6=65 ms to 210 ms; 9=260 ms to 900 ms; 10=1 s to 3.5 s; 13=4 s to 13 s; 14=17 s to 64 s; other=Others (reserved (setting prohibited))
0x6088 PCI_RC_DEVCS2 — Device Control 2/Status 2 Register
  fields as PCI_EP_DEVCS2_F0
{0x608C+0x1000*i} PCI_EP_LINKC2_F{i} (i=0..1) reset 0xE — Link Capabilities 2 (Function #i)
  [7:1] SLSV — Supported Link Speeds Vector
0x608C PCI_RC_LINKC2 reset 0xE — Link Capabilities 2 Register
  [7:1] SLSV — Supported Link Speeds Vector
{0x6090+0x1000*i} PCI_EP_LINKCS2_F{i} (i=0..1) reset 0x3 — Link Control 2/Status 2 (Function #n)
  [21] LER — Link Equalization Request
  [20] EP3S ro — Equalization Phase 3 Successful
  [19] EP2S ro — Equalization Phase 2 Successful
  [18] EP1S ro — Equalization Phase 1 Successful
  [17] EQC ro — Equalization Complete
  [16] CDL ro — Current De-emphasis Level
    0=-6 dB (Default); 1=-3.5 dB
  [15:12] CPD — Compliance Preset De-emphasis
    0=-6 dB (Default); 1=-3.5 dB
  [11] CSOS — Compliance SOS
  [10] EMC — Enter Modified Compliance
    0=Compliance Pattern (Default); 1=Modified Compliance Pattern
  [9:7] TM — Transmit Margin
  [5] HASD — Hardware Autonomous Speed Disable
    0=Support of Link Speed Change (Enable); 1=Not Support of Link Speed Change (Disable)
  [4] ETC — Enter Compliance
  [3:0] TLS — Target Link Speed
    1=2.5 GT/s Target Link Speed; 2=5.0 GT/s Target Link Speed; 3=8.0 GT/s Target Link Speed (Default); 4=16.0 GT/s Target Link Speed (prohibited); other=Others (Reserved)
0x6090 PCI_RC_LINKCS2 reset 0x3 — Link Control 2/Status 2 Register
  [21] LER — Link Equalization Request
  [20] EP3S ro — Equalization Phase 3 Successful
  [19] EP2S ro — Equalization Phase 2 Successful
  [18] EP1S ro — Equalization Phase 1 Successful
  [17] EQC ro — Equalization Complete
  [16] CDL ro — Current De-emphasis Level
    0=-6 dB (Default); 1=-3.5 dB
  [15:12] CPD — Compliance Preset De-emphasis
    0=-6 dB (Default); 1=-3.5 dB
  [11] CSOS — Compliance SOS
  [10] EMC — Enter Modified Compliance
    values as PCI_EP_LINKCS2_F0.EMC
  [9:7] TM — Transmit Margin
  [6] SD — Selectable Deemphasis
    0=-6 dB; 1=-3.5 dB
  [5] HASD — Hardware Autonomous Speed Disable
    0=Support of Link Speed Change (Enable); 1=not Support of Link Speed Change (Disable)
  [4] ETC — Enter Compliance
  [3:0] TLS — Target Link Speed
    values as PCI_EP_LINKCS2_F0.TLS
{0x60A0+0x1000*i} PCI_EP_BARMSK00L_F{i} (i=0..1) reset 0x1FFFFFFF — Base Address Register Mask00 (Lower) (Function #i)
  [31:0] BARM00L — Base Address Register Mask00 (Lower)
0x60A0 PCI_RC_BARMSK00L reset 0x1FFFFFFF — Base Address Register Mask00 (Lower)
  [31:0] BARM00L
{0x60A4+0x1000*i} PCI_EP_BARMSK00U_F{i} (i=0..1) — Base Address Register Mask00 (Upper) (Function #i)
  [31:0] BARM00U — Base Address Register Mask00 (Upper)
0x60A4 PCI_RC_BARMSK00U — Base Address Register Mask00 (Upper)
  [31:0] BARM00U
{0x60A8+0x1000*i} PCI_EP_BARMSK01L_F{i} (i=0..1) reset 0xFFFFFFFF — Base Address Register Mask01 (Lower) (Function #i)
  [31:0] BARM01L — Base Address Register Mask01 (Lower)
{0x60AC+0x1000*i} PCI_EP_BARMSK01U_F{i} (i=0..1) reset 0x7F — Base Address Register Mask01 (Upper) (Function #i)
  [31:0] BARM01U — Base Address Register Mask01 (Upper)
{0x60B0+0x1000*i} PCI_EP_BARMSK02L_F{i} (i=0..1) reset 0x1FFF — Base Address Register Mask02 (Lower) (Function #i)
  [31:0] BARM02L — Base Address Register Mask02 (Lower)
{0x60B4+0x1000*i} PCI_EP_BARMSK02U_F{i} (i=0..1) — Base Address Register Mask02 (Upper) (Function #i)
  [31:0] BARM02U — Base Address Register Mask02 (Upper)
{0x60C8+0x1000*i} PCI_EP_BSIZE00_01_F{i} (i=0..1) — Base Size 00/01 (Function #i)
  [25:16] BS01 — Base Size 01
  [9:0] BS00 — Base Size 00
0x60C8 PCI_RC_BSIZE00_01 — Base Size 00/01 Register
  [9:0] BS00 — Base Size 00
{0x60CC+0x1000*i} PCI_EP_BSIZE02_03_F{i} (i=0..1) — Base Size 02/03 (Function #i)
  [25:16] BS03 — Base Size 03
  [9:0] BS02 — Base Size 02
{0x60D0+0x1000*i} PCI_EP_BSIZE04_05_F{i} (i=0..1) — Base Size 04/05 (Function #i)
  [25:16] BS05 — Base Size 05
  [9:0] BS04 — Base Size 04
{0x60D4+0x1000*i} PCI_EP_BSIZE06_F{i} (i=0..1) — Base Size 06 (Function #i)
  [9:0] BS06 — Base Size 06
{0x60D8+0x1000*i} PCI_EP_TSUPPORT00_01_02_F{i} (i=0..1) reset 0x333333 — Type Supported 00/01/02 (Function #i)
  [23:16] TS02 — Type Supported 02
  [15:8] TS01 — Type Supported 01
  [7:0] TS00 — Type Supported 00
0x60D8 PCI_RC_TSUPPORT00_01_02 reset 0x33 — Type Supported 00/01/02 Register
  [7:0] TS00 — Type Supported 00
{0x60E0+0x1000*i} PCI_EP_MSICAP_F{i} (i=0..1) reset 0x18A6005 — MSI Capability (Function #i)
  [24] PVMC ro — Per-vector masking capable
  [23] AC64 ro — 64-bit Address Capable
  [22:20] MME — Multiple Message Enable
    0=1 (default); 1=2; 2=4; 3=8; 4=16; 5=32
  [19:17] MMC ro — Multiple Message Capable
    0=1; 1=2; 2=4; 3=8; 4=16; 5=32 (default)
  [16] MSIE — MSI Enable
  [15:8] NCP ro — Next Capability Pointer
  [7:0] CID ro — Capability ID
{0x60E4+0x1000*i} PCI_EP_MSGADR_F{i} (i=0..1) — Message Address (Function #i)
  [31:2] MA — Message Address
{0x60E8+0x1000*i} PCI_EP_MSGUADR_F{i} (i=0..1) — Message Upper Address (Function #i)
  [31:0] MUA — Message Upper Address
{0x60EC+0x1000*i} PCI_EP_MSGDAT_F{i} (i=0..1) — Message Data (Function #i)
  [15:0] MD — Message Data
{0x60F0+0x1000*i} PCI_EP_MSKBIT_F{i} (i=0..1) — Mask Bits (Function #i)
  [31:0] MB — Mask Bits
{0x60F4+0x1000*i} PCI_EP_PENDBIT_F{i} (i=0..1) — Pending Bits (Function #i)
  [31:0] PB — Pending Bits
{0x6100+0x1000*i} PCI_EP_ADVERC_F{i} (i=0..1) reset 0x15010001 — Advanced Error Reporting Capability (Function #i)
  [31:20] NCO ro — Next Capability Offset
  [19:16] CV — Capability Version
  [15:0] PCIEECID ro — PCI Express Extended Capability ID
0x6100 PCI_RC_ADVERC reset 0x15010001 — Advanced Error Reporting Capability Register
  [31:20] NCO — Next Capability Offset
  [19:16] CV — Capability Version
  [15:0] PCIEECID ro — PCI Express Extended Capability ID
{0x6104+0x1000*i} PCI_EP_UNCESTS_F{i} (i=0..1) — Uncorrectable Error Status Register (Function #i)
  [all] fields
    0=No error detected; 1=Error detected
  [20] URES — Unsupported Request Error Status
  [19] ECRCESO — ECRC Error Status (Optional)
  [18] MTLPS — Malformed TLP Status
  [17] ROSO — Receiver Overflow Status (Optional)
  [16] UCS — Unexpected Completion Status
  [15] CASO — Completer Abort Status (Optional)
  [14] CTS — Completion Timeout Status
  [12] PTLPRS — Poisoned TLP Received Status
  [4] DLPES — Data Link Protocol Error Status
0x6104 PCI_RC_UNCESTS — Uncorrectable Error Status Register
  fields as PCI_EP_UNCESTS_F0
{0x6108+0x1000*i} PCI_EP_UNCEMASK_F{i} (i=0..1) — Uncorrectable Error Mask Register (Function #i)
  [20] UREM — Unsupported Request Error Mask
    0=No mask; 1=Send Error Message, record header to Header Log register, mask Update of First Error Pointer
  [19] ECRCEMO — ECRC Error Mask (Optional)
    0=No mask; 1=Mask
  [18] MTLPM — Malformed TLP Mask
    values as UREM
  [17] ROMO — Receiver Overflow Mask (Optional)
    0=No mask; 1=Send Error Message, Mask Update of First Error Pointer
  [16] UCM — Unexpected Completion Mask
    values as UREM
  [15] CAMO — Completer Abort Mask (Optional)
    values as UREM
  [14] CTM — Completion Timeout Mask
    values as ROMO
  [12] PTLPRM — Poisoned TLP Received Mask
    values as UREM
  [4] DLPEM — Data Link Protocol Error Mask
    values as ROMO
0x6108 PCI_RC_UNCEMASK — Uncorrectable Error Mask Register
  fields as PCI_EP_UNCEMASK_F0
{0x610C+0x1000*i} PCI_EP_UNCESVY_F{i} (i=0..1) reset 0x460010 — Uncorrectable Error Severity Register (Function #i)
  [all] fields
    0=Non-Fatal Error; 1=Fatal Error
  [20] URES — Unsupported Request Error Severity
  [19] ECRCESO — ECRC Error Severity (Optional)
  [18] MTLPS — Malformed TLP Severity
  [17] ROSO — Receiver Overflow Severity (Optional)
  [16] UCS — Unexpected Completion Severity
  [15] CASO — Completer Abort Severity (Optional)
  [14] CTS — Completion Timeout Severity
  [12] PTLPRS — Poisoned TLP Received Severity
  [4] DLPES — Data Link Protocol Error Severity
0x610C PCI_RC_UNCESVY reset 0x460010 — Uncorrectable Error Severity Register
  fields as PCI_EP_UNCESVY_F0
{0x6110+0x1000*i} PCI_EP_CESTS_F{i} (i=0..1) ro — Correctable Error Status Register (Function #i)
  [all] fields
    0=No error detected; 1=Error detected
  [13] ANFES — Advisory Non-Fatal Error Status
  [12] RTTS — Replay Timer Timeout Status
  [8] REPLAYNUMRS — REPLAY_NUM Rollover Status
  [7] BDLLPS — Bad DLLP Status
  [6] BTLPS — Bad TLP Status
  [0] RES — Receiver Error Status (optional)
0x6110 PCI_RC_CESTS — Correctable Error Status Register
  fields as PCI_EP_CESTS_F0
{0x6114+0x1000*i} PCI_EP_CEMASK_F{i} (i=0..1) — Correctable Error Mask Register (Function #i)
  [13] ANFEM — Advisory Non-Fatal Error Mask
    0=No mask; 1=Mask Advisory Non-Fatal Error handling (Mask updating First Error Pointer and Header Logging and sending Error Message)
  [12] RTTM — Replay Timer Timeout Mask
    0=No mask; 1=Mask error message transmission
  [8] REPLAYNUMRM — REPLAY_NUM Rollover Mask
    0=No mask; 1=Mask error message transmission
  [7] BDLLPM — Bad DLLP Mask
    0=No mask; 1=Mask error message transmission
  [6] BTLPM — Bad TLP Mask
    0=No mask; 1=Mask error message transmission
  [0] REM — Receiver Error Mask (optional)
    0=No mask; 1=Mask error message transmission
0x6114 PCI_RC_CEMASK — Correctable Error Mask Register
  fields as PCI_EP_CEMASK_F0
{0x6118+0x1000*i} PCI_EP_ADVECC_F{i} (i=0..1) reset 0xA0 — Advanced Error Capabilities and Control Register (Function #i)
  [8] ECRCCE — ECRC Check Enable
    0=Disable (Default); 1=Enable
  [7] ECRCCC ro — ECRC Check Capable
    0=None; 1=Yes (Default)
  [6] ECRCGE — ECRC Generation Enable
    0=Disable (Default); 1=Enable
  [5] ECRCGC ro — ECRC Generation Capable
    0=None; 1=Yes (Default)
  [4:0] FEP ro — First Error Pointer
0x6118 PCI_RC_ADVECC reset 0xA0 — Advanced Error Capabilities and Control Register
  fields as PCI_EP_ADVECC_F0
{0x611C+0x1000*i} PCI_EP_HLOG0_F{i} (i=0..1) ro — Header Log Register 0 (Function #i)
  [31:0] HTLPE0 — Header of TLP associated with error 0
0x611C PCI_RC_HLOG0 ro — Header Log Register 0
  [31:0] HTLPE0 — Header of TLP associated with error 0
0x6120 PCI_EP_HLOG1_Fi ro — Header Log Register 1 (Function #i)
  [31:0] HTLPE1 — Header of TLP associated with error 1
0x6120 PCI_RC_HLOG1 ro (alternate view of PCI_EP_HLOG1_Fi) — Header Log Register 1
  [31:0] HTLPE1 — Header of TLP associated with error 1
{0x6124+0x1000*i} PCI_EP_HLOG2_F{i} (i=0..1) ro — Header Log Register 2 (Function #i)
  [31:0] HTLPE2 — Header of TLP associated with error 2
0x6124 PCI_RC_HLOG2 ro — Header Log Register 2
  [31:0] HTLPE2 — Header of TLP associated with error 2
{0x6128+0x1000*i} PCI_EP_HLOG3_F{i} (i=0..1) ro — Header Log Register 3 (Function #i)
  [31:0] HTLPE3 — Header of TLP associated with error 3
0x6128 PCI_RC_HLOG3 ro — Header Log Register 3
  [31:0] HTLPE3 — Header of TLP associated with error 3
0x612C PCI_RC_ROOTEC — Root Error Command
  [2] FERE — Fatal Error Reporting Enable
  [1] NFERE — Non-Fatal Error Reporting Enable
  [0] CERE — Correctable Error Reporting Enable
0x6130 PCI_RC_ROOTES — Root Error Status
  [6] FEMR — Fatal Error Message Received
  [5] NFEMR — Non-Fatal Error Message Received
  [4] FUF — First Uncorrectable Fatal
  [3] MERRFATALNONFATALR — Multiple ERR_FATALNONFATAL Received
  [2] ERRFATALNONFATALR — ERR_FATALNONFATAL Received
  [1] MERRCORR — Multiple ERR_COR Received
  [0] ERRCORR — ERR_COR Received
0x6134 PCI_RC_ERRSI ro — Error Source Identification Register
  [31:16] ERRFATALNONFATALSI — ERR_FATALNONFATAL Source Identification
  [15:0] ERRCORSI — ERR_COR Source Identification
{0x6150+0x1000*i} PCI_EP_DEVSNEXTC_F{i} (i=0..1) reset 0x1B010003 — Device Serial Number Extended Capability Register (Function #i)
  fields as PCI_EP_ADVERC_F0
0x6150 PCI_RC_DEVSNEXTC reset 0x1B010003 — Device Serial Number Extended Capability Register
  fields as PCI_EP_ADVERC_F0
{0x6154+0x1000*i} PCI_EP_SNL_F{i} (i=0..1) — Serial Number Register (Lower DW) (Function #i)
  [31:0] PCIEDSN_LDW — PCI Express Device Serial Number (Lower DW)
0x6154 PCI_RC_SNL — Serial Number Register (Lower DW)
  [31:0] PCIEDSN_LDW — PCI Express Device Serial Number (Lower DW)
{0x6158+0x1000*i} PCI_EP_SNU_F{i} (i=0..1) — Serial Number Register (Upper DW) (Function #i)
  [31:0] PCIEDSN_UDW — PCI Express Device Serial Number (Upper DW)
0x6158 PCI_RC_SNU — Serial Number Register (Upper DW)
  [31:0] PCIEDSN_UDW — PCI Express Device Serial Number (Upper DW)
0x61B0 PCI_EP_SPEECH_F0 reset 0x10019 — Secondary PCI Express Extended Capability Header (Function #0)
  fields as PCI_EP_ADVERC_F0
0x61B0 PCI_RC_SPEECH reset 0x10019 (alternate view of PCI_EP_SPEECH_F0) — Secondary PCI Express Extended Capability Header
  fields as PCI_EP_ADVERC_F0
0x61B4 PCI_EP_LINKC3_F0 — Link Control 3 Register (Function #0)
  [15:9] ELSKPOSGV — Enable Lower SKP OS Generation Vector
0x61B4 PCI_RC_LINKC3 (alternate view of PCI_EP_LINKC3_F0) — Link Control 3 Register
  [15:9] ELSKPOSGV — Enable Lower SKP OS Generation Vector
  [1] LERIE — Link Equalization Request Interrupt Enable
  [0] PE — Perform Equalization
0x61B8 PCI_EP_LESTA_F0 — Lane Error Status Register (Function #0)
  [1:0] LESB — Lane Error Status Bits
0x61B8 PCI_RC_LESTA (alternate view of PCI_EP_LESTA_F0) — Lane Error Status Register
  [3:0] LESB — Lane Error Status Bits
0x61BC PCI_EP_LEQCTL_F0 ro — Lane Equalization Control Register (Function #0)
  [30:28] UPRPH1 — Upstream Port 8.0 GTs Receiver Preset Hint Lane1
  [27:24] UPTP1 — Upstream Port 8.0 GTs Transmitter Preset Lane1
  [22:20] DPRPH1 — Downstream Port 8.0 GTs Receiver Preset Hint Lane1
  [19:16] DPTP1 — Downstream Port 8.0 GTs Transmitter Preset Lane1
  [14:12] UPRPH0 — Upstream Port 8.0 GTs Receiver Preset Hint Lane0
  [11:8] UPTP0 — Upstream Port 8.0 GTs Transmitter Preset Lane0
  [6:4] DPRPH0 — Downstream Port 8.0 GTs Receiver Preset Hint Lane0
  [3:0] DPTP0 — Downstream Port 8.0 GTs Transmitter Preset Lane0
0x61BC PCI_RC_LEQCTL reset 0x7F7F7F7F (alternate view of PCI_EP_LEQCTL_F0) — Lane Equalization Control Register
  fields as PCI_EP_LEQCTL_F0
